# AC7842x register map
Vendor: AutoChips; Series: AC78; File version: 1.0
CPU: CM4 r0p1, little endian, MPU, FPU, VTOR, 4 interrupt priority bits
Registers are 32-bit, read-write, reset 0x0 unless marked. A register's access mark holds for its fields unless they carry their own. Offsets are from the block's base; [hi:lo] are bit positions.

## MCM — Core Platform Miscellaneous Control Module
Base 0xE008000C
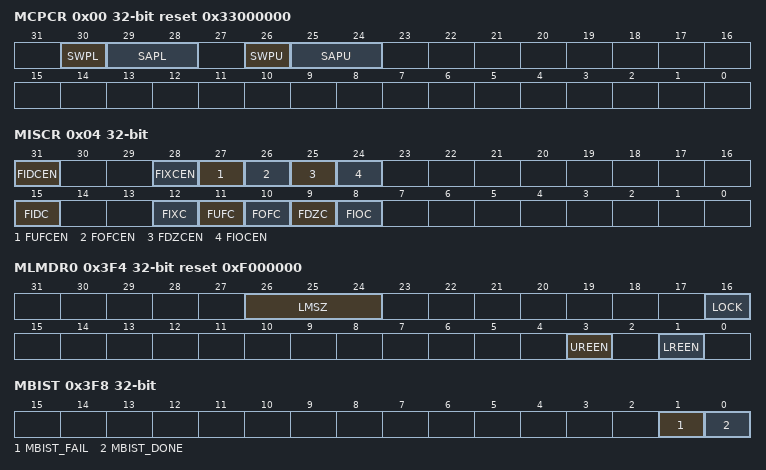
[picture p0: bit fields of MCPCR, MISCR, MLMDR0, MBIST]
0x00 MCPCR reset 0x33000000 — MCM Core Platform Control Register
  [30] SWPL — SRAM_L write protect, When this bit is set to 1, writing to SRAM_L will generate a bus error
    0=SRAM_L write protect disable; 1=SRAM_L write protect enable
  [29:28] SAPL — access SRAM_L arbitration priority
    0=SRAM_L round-robin; 3=fix priority,DMA HigherThan D-BUS HigherThan I-BUS,when access to SRAM_L
  [26] SWPU — SRAM_U write protect, When this bit is set to 1, writing to SRAM_U will generate a bus error
    0=SRAM_U write protect disable; 1=SRAM_U write protect enable
  [25:24] SAPU — access SRAM_U arbitration priority
    0=SRAM_U round-robin; 3=fix priority,DMA HigherThan S-BUS,when access to SRAM_U
0x04 MISCR — MCM Interrupt Status and Control Register
  [31] FIDCEN — FPU Input Denormal Interrupt Enable
    0=Disable; 1=Enable
  [28] FIXCEN — FPU Inexact Interrupt Enable
    0=Disable; 1=Enable
  [27] FUFCEN — FPU Underflow Interrupt Enable
    0=Disable; 1=Enable
  [26] FOFCEN — FPU Overflow Interrupt Enable
    0=Disable; 1=Enable
  [25] FDZCEN — FPU Divide-by-Zero Interrupt Enable
    0=Disable; 1=Enable
  [24] FIOCEN — FPU Invalid Operation Interrupt Enable
    0=Disable; 1=Enable
  [15] FIDC ro — FPU Input Denormal Interrupt request status. After this field is set, it remains set until software clears FPSCR[IDC].
    0=No Interrupt; 1=Interrupt Occurred
  [12] FIXC ro — FPU Inexact Interrupt request status. After this field is set, it remains set until software clears FPSCR[IXC].
    0=No Interrupt; 1=Interrupt Occurred
  [11] FUFC ro — FPU Underflow Interrupt request status After this field is set, it remains set until software clears FPSCR[UFC].
    0=No Interrupt; 1=Interrupt Occurred
  [10] FOFC ro — FPU Overflow Interrupt request status. After this field is set, it remains set until software clears FPSCR[OFC].
    0=No Interrupt; 1=Interrupt Occurred
  [9] FDZC ro — FPU Divide-by-Zero Interrupt request status. After this field is set, it remains set until software clears FPSCR[DZC].
    0=No Interrupt; 1=Interrupt Occurred
  [8] FIOC ro — FPU Invalid Operation Interrupt request status. After this field is set, it remains set until software clears FPSCR[IOC].
    0=No Interrupt; 1=Interrupt Occurred
0x3F4 MLMDR0 reset 0xF000000 — MCM Local MCM Local Memory Descriptor Register0
  [26:24] LMSZ ro — SRAM Size(Include up and low)
  [16] LOCK — Lock LMDR0,Once locked,only reset can clear this bit
    0=unLocked,LMDR0 can be written; 1=Locked,LMDR0 can not be written
  [3] UREEN — SRAM_U ECC Enable Read Check
    0=Disable; 1=Enable
  [1] LREEN — SRAM_L ECC Enable Read Check
    0=Disable; 1=Enable
0x3F8 MBIST ro — MCM Local Memory BIST Register
  [1] MBIST_FAIL — MBIST test fail status
    0=when MBIST_DONE is 1, MBIST test success; 1=when MBIST_DONE is 1, MBIST test fail
  [0] MBIST_DONE — MBIST test done status
    0=MBIST test disable; 1=MBIST test done
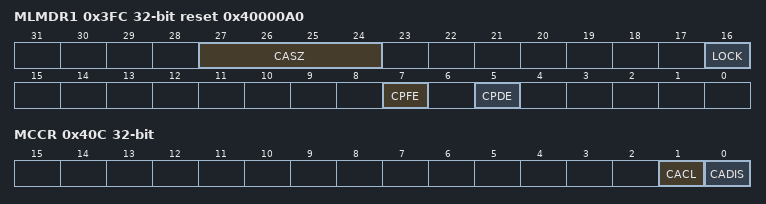
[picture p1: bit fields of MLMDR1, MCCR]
0x3FC MLMDR1 reset 0x40000A0 — MCM Local MCM Local Memory Descriptor Register1
  [27:24] CASZ ro — Cache Size
  [16] LOCK — Lock LMDR1,Once locked,only reset can clear this bit
    0=unLocked,LMDR1 can be written; 1=Locked,LMDR1 can not be written
  [7] CPFE — Cache parity function enable control
    0=Disable; 1=Enable
  [5] CPDE — Cache parity error detect enable control
    0=Disable; 1=Enable
0x400 LMPECR — MCM Local Memory Cache ECC Enable Control Register
  [20] CPEIEN — Cache ECC error interrupt enable
    0=Disable; 1=Enable
0x404 LMPEIR — MCM Local Memory Cache ECC Error Status Register
0x408 LMFAR ro — MCM Local Memory Cache ECC Error Address Register
0x40C MCCR — MCM Cache Control Register
  [1] CACL — Cache clear bit,when this bit is set to 1,cache will be cleared
    0=no effect; 1=Clear Cache
  [0] CADIS — Cache Enable
    0=Enable; 1=Disable
0x474 MNCR — MCM NMI Control Register
  [0] NMI_EN — NMI Enable
    0=Disable; 1=Enable
